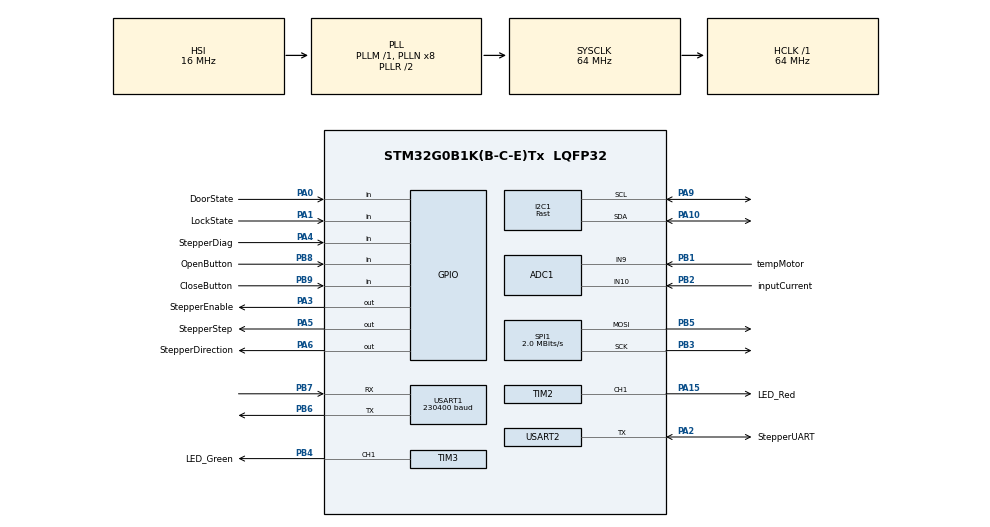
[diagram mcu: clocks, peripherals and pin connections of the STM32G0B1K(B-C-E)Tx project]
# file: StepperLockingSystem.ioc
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ADC1.DMAContinuousRequests=DISABLE
ADC1.DataAlign=ADC_DATAALIGN_RIGHT
ADC1.EOCSelection=ADC_EOC_SEQ_CONV
ADC1.NbrOfConversion=1
ADC1.NbrOfConversionFlag=0
ADC1.SamplingTimeCommon1=ADC_SAMPLETIME_160CYCLES_5
ADC1.SelectedChannel=ADC_CHANNEL_TEMPSENSOR|ADC_CHANNEL_VREFINT|ADC_CHANNEL_9|ADC_CHANNEL_10
ADC1.Sequencer=NOT_FULLY_CONFIGURABLE
ADC1.master=1
Dma.ADC1.0.Direction=DMA_PERIPH_TO_MEMORY
Dma.ADC1.0.EventEnable=DISABLE
Dma.ADC1.0.Instance=DMA1_Channel1
Dma.ADC1.0.MemDataAlignment=DMA_MDATAALIGN_HALFWORD
Dma.ADC1.0.MemInc=DMA_MINC_ENABLE
Dma.ADC1.0.Mode=DMA_NORMAL
Dma.ADC1.0.PeriphDataAlignment=DMA_PDATAALIGN_HALFWORD
Dma.ADC1.0.PeriphInc=DMA_PINC_DISABLE
Dma.ADC1.0.Polarity=HAL_DMAMUX_REQ_GEN_RISING
Dma.ADC1.0.Priority=DMA_PRIORITY_LOW
Dma.ADC1.0.RequestNumber=1
Dma.ADC1.0.SignalID=NONE
Dma.ADC1.0.SyncEnable=DISABLE
Dma.ADC1.0.SyncPolarity=HAL_DMAMUX_SYNC_NO_EVENT
Dma.ADC1.0.SyncRequestNumber=1
Dma.ADC1.0.SyncSignalID=NONE
Dma.Request0=ADC1
Dma.Request1=SPI1_TX
Dma.Request2=USART2_RX
Dma.Request3=USART2_TX
Dma.SPI1_TX.1.Direction=DMA_MEMORY_TO_PERIPH
Dma.SPI1_TX.1.EventEnable=DISABLE
Dma.SPI1_TX.1.Instance=DMA1_Channel2
Dma.SPI1_TX.1.MemDataAlignment=DMA_MDATAALIGN_BYTE
Dma.SPI1_TX.1.MemInc=DMA_MINC_ENABLE
Dma.SPI1_TX.1.Mode=DMA_NORMAL
Dma.SPI1_TX.1.PeriphDataAlignment=DMA_PDATAALIGN_BYTE
Dma.SPI1_TX.1.PeriphInc=DMA_PINC_DISABLE
Dma.SPI1_TX.1.Polarity=HAL_DMAMUX_REQ_GEN_RISING
Dma.SPI1_TX.1.Priority=DMA_PRIORITY_MEDIUM
Dma.SPI1_TX.1.RequestNumber=1
Dma.SPI1_TX.1.SignalID=NONE
Dma.SPI1_TX.1.SyncEnable=DISABLE
Dma.SPI1_TX.1.SyncPolarity=HAL_DMAMUX_SYNC_NO_EVENT
Dma.SPI1_TX.1.SyncRequestNumber=1
Dma.SPI1_TX.1.SyncSignalID=NONE
Dma.USART2_RX.2.Direction=DMA_PERIPH_TO_MEMORY
Dma.USART2_RX.2.EventEnable=DISABLE
Dma.USART2_RX.2.Instance=DMA1_Channel3
Dma.USART2_RX.2.MemDataAlignment=DMA_MDATAALIGN_BYTE
Dma.USART2_RX.2.MemInc=DMA_MINC_ENABLE
Dma.USART2_RX.2.Mode=DMA_NORMAL
Dma.USART2_RX.2.PeriphDataAlignment=DMA_PDATAALIGN_BYTE
Dma.USART2_RX.2.PeriphInc=DMA_PINC_DISABLE
Dma.USART2_RX.2.Polarity=HAL_DMAMUX_REQ_GEN_RISING
Dma.USART2_RX.2.Priority=DMA_PRIORITY_LOW
Dma.USART2_RX.2.RequestNumber=1
Dma.USART2_RX.2.SignalID=NONE
Dma.USART2_RX.2.SyncEnable=DISABLE
Dma.USART2_RX.2.SyncPolarity=HAL_DMAMUX_SYNC_NO_EVENT
Dma.USART2_RX.2.SyncRequestNumber=1
Dma.USART2_RX.2.SyncSignalID=NONE
Dma.USART2_TX.3.Direction=DMA_MEMORY_TO_PERIPH
Dma.USART2_TX.3.EventEnable=DISABLE
Dma.USART2_TX.3.Instance=DMA1_Channel4
Dma.USART2_TX.3.MemDataAlignment=DMA_MDATAALIGN_BYTE
Dma.USART2_TX.3.MemInc=DMA_MINC_ENABLE
Dma.USART2_TX.3.Mode=DMA_NORMAL
Dma.USART2_TX.3.PeriphDataAlignment=DMA_PDATAALIGN_BYTE
Dma.USART2_TX.3.PeriphInc=DMA_PINC_DISABLE
Dma.USART2_TX.3.Polarity=HAL_DMAMUX_REQ_GEN_RISING
Dma.USART2_TX.3.Priority=DMA_PRIORITY_LOW
Dma.USART2_TX.3.RequestNumber=1
Dma.USART2_TX.3.SignalID=NONE
Dma.USART2_TX.3.SyncEnable=DISABLE
Dma.USART2_TX.3.SyncPolarity=HAL_DMAMUX_SYNC_NO_EVENT
Dma.USART2_TX.3.SyncRequestNumber=1
Dma.USART2_TX.3.SyncSignalID=NONE
FREERTOS.Tasks01=defaultTask,24,512,StartDefaultTask,As weak,NULL,Dynamic,NULL,NULL
FREERTOS.configCHECK_FOR_STACK_OVERFLOW=2
FREERTOS.configMAX_TASK_NAME_LEN=24
FREERTOS.configRECORD_STACK_HIGH_ADDRESS=1
FREERTOS.configTIMER_TASK_STACK_DEPTH=256
FREERTOS.configTOTAL_HEAP_SIZE=30000
I2C1.I2C_Speed_Mode=I2C_Fast
I2C1.Timing=0x00602173
Mcu.Family=STM32G0
Mcu.Name=STM32G0B1K(B-C-E)Tx
Mcu.Package=LQFP32
NVIC.ADC1_COMP_IRQn=true\:3\:0\:true\:false\:true\:true\:true\:true\:true
NVIC.DMA1_Ch4_7_DMA2_Ch1_5_DMAMUX1_OVR_IRQn=true\:3\:0\:false\:false\:true\:true\:false\:true\:true
NVIC.DMA1_Channel1_IRQn=true\:3\:0\:false\:false\:true\:true\:false\:true\:true
NVIC.DMA1_Channel2_3_IRQn=true\:3\:0\:false\:false\:true\:true\:false\:true\:true
NVIC.I2C1_IRQn=true\:3\:0\:false\:false\:true\:true\:true\:true\:true
NVIC.SPI1_IRQn=true\:3\:0\:false\:false\:true\:true\:true\:true\:true
NVIC.TIM6_DAC_LPTIM1_IRQn=true\:3\:0\:false\:false\:true\:false\:false\:true\:true
NVIC.TimeBase=TIM6_DAC_LPTIM1_IRQn
NVIC.TimeBaseIP=TIM6
NVIC.USART2_LPUART2_IRQn=true\:3\:0\:false\:false\:true\:true\:true\:true\:true
PA0.GPIO_Label=DoorState
PA0.Signal=GPIO_Input
PA1.GPIO_Label=LockState
PA1.Signal=GPIO_Input
PA10.Mode=I2C
PA10.Signal=I2C1_SDA
PA13.Mode=Serial_Wire
PA13.Signal=SYS_SWDIO
PA14-BOOT0.Mode=Serial_Wire
PA14-BOOT0.Signal=SYS_SWCLK
PA15.GPIO_Label=LED_Red
PA15.Signal=S_TIM2_CH1_ETR
PA2.GPIO_Label=StepperUART
PA2.Mode=Half_duplex(single_wire_mode)
PA2.Signal=USART2_TX
PA3.GPIO_Label=StepperEnable
PA3.PinState=GPIO_PIN_SET
PA3.Signal=GPIO_Output
PA4.GPIO_Label=StepperDiag
PA4.Signal=GPIO_Input
PA5.GPIO_Label=StepperStep
PA5.Signal=GPIO_Output
PA6.GPIO_Label=StepperDirection
PA6.Signal=GPIO_Output
PA9.Mode=I2C
PA9.Signal=I2C1_SCL
PB1.GPIO_Label=tempMotor
PB1.Mode=IN9
PB1.Signal=ADC1_IN9
PB2.GPIO_Label=inputCurrent
PB2.Mode=IN10
PB2.Signal=ADC1_IN10
PB3.Mode=TX_Only_Simplex_Unidirect_Master
PB3.Signal=SPI1_SCK
PB4.GPIO_Label=LED_Green
PB4.Signal=S_TIM3_CH1
PB5.Mode=TX_Only_Simplex_Unidirect_Master
PB5.Signal=SPI1_MOSI
PB6.Mode=Asynchronous
PB6.Signal=USART1_TX
PB7.Mode=Asynchronous
PB7.Signal=USART1_RX
PB8.GPIO_Label=OpenButton
PB8.Signal=GPIO_Input
PB9.GPIO_Label=CloseButton
PB9.Signal=GPIO_Input
ProjectManager.HeapSize=0x200
ProjectManager.StackSize=0x400
ProjectManager.TargetToolchain=CMake
RCC.ADCFreq_Value=64000000
RCC.AHBFreq_Value=64000000
RCC.CortexFreq_Value=64000000
RCC.EXTERNAL_CLOCK_VALUE=48000
RCC.HCLKFreq_Value=64000000
RCC.HSE_VALUE=16000000
RCC.HSI48_VALUE=48000000
RCC.HSI_VALUE=16000000
RCC.LSE_VALUE=32768
RCC.SYSCLKFreq_VALUE=64000000
RCC.SYSCLKSource=RCC_SYSCLKSOURCE_PLLCLK
RCC.USBFreq_Value=48000000
RCC.VCOOutputFreq_Value=128000000
SH.S_TIM2_CH1_ETR.0=TIM2_CH1,PWM Generation1 CH1
SH.S_TIM3_CH1.0=TIM3_CH1,PWM Generation1 CH1
SPI1.BaudRatePrescaler=SPI_BAUDRATEPRESCALER_32
SPI1.CalculateBaudRate=2.0 MBits/s
SPI1.DataSize=SPI_DATASIZE_8BIT
SPI1.Direction=SPI_DIRECTION_2LINES
SPI1.Mode=SPI_MODE_MASTER
SPI1.VirtualType=VM_MASTER
TIM2.Channel-PWM\ Generation1\ CH1=TIM_CHANNEL_1
TIM2.ClockDivision=TIM_CLOCKDIVISION_DIV2
TIM2.Period=255
TIM2.TIM_MasterSlaveMode=TIM_MASTERSLAVEMODE_ENABLE
TIM3.Channel-PWM\ Generation1\ CH1=TIM_CHANNEL_1
TIM3.ClockDivision=TIM_CLOCKDIVISION_DIV2
TIM3.Period=255
USART1.BaudRate=230400
USART1.Mode=MODE_TX_RX
USART1.VirtualMode-Asynchronous=VM_ASYNC
USART2.VirtualMode-Half_duplex(single_wire_mode)=VM_ASYNC
VP_ADC1_TempSens_Input.Mode=IN-TempSens
VP_ADC1_Vref_Input.Mode=IN-Vrefint
VP_FREERTOS_VS_CMSIS_V2.Mode=CMSIS_V2
VP_SYS_VS_DBSignals.Mode=DisableDeadBatterySignals
VP_SYS_VS_tim6.Mode=TIM6
VP_TIM2_VS_ClockSourceINT.Mode=Internal
VP_TIM3_VS_ClockSourceINT.Mode=Internal
board=custom

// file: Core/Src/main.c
/* USER CODE BEGIN Header */
/**
  ******************************************************************************
  * @file           : main.c
  * @brief          : Main program body
  ******************************************************************************
  * @attention
  *
  * Copyright (c) 2025 STMicroelectronics.
  * All rights reserved.
  *
  * This software is licensed under terms that can be found in the LICENSE file
  * in the root directory of this software component.
  * If no LICENSE file comes with this software, it is provided AS-IS.
  *
  ******************************************************************************
  */
/* USER CODE END Header */
#include "main.h"
#include "cmsis_os.h"
#include "adc.h"
#include "dma.h"
#include "i2c.h"
#include "spi.h"
#include "tim.h"
#include "usart.h"
#include "gpio.h"

/* USER CODE BEGIN Includes */
#include "CFunctions.h"
#include "../../../src/customFaultHandler.h"
/* USER CODE END Includes */

void SystemClock_Config(void);
void MX_FREERTOS_Init(void);

int main(void)
{

  /* MCU Configuration--------------------------------------------------------*/

  /* Reset of all peripherals, Initializes the Flash interface and the Systick. */
  HAL_Init();

  /* Configure the system clock */
  SystemClock_Config();

  /* Initialize all configured peripherals */
  MX_GPIO_Init();
  MX_DMA_Init();
  MX_I2C1_Init();
  MX_SPI1_Init();
  MX_TIM2_Init();
  MX_TIM3_Init();
  MX_ADC1_Init();
  MX_USART2_UART_Init();
  MX_USART1_UART_Init();

  /* Init scheduler */
  osKernelInitialize();

  /* Call init function for freertos objects (in cmsis_os2.c) */
  MX_FREERTOS_Init();

  /* Start scheduler */
  osKernelStart();

  /* We should never get here as control is now taken by the scheduler */

  /* Infinite loop */
  while (1)
  {
    faultHandlerStepperFailsafe();
  }
}

void SystemClock_Config(void)
{
  RCC_OscInitTypeDef RCC_OscInitStruct = {0};
  RCC_ClkInitTypeDef RCC_ClkInitStruct = {0};

  /** Configure the main internal regulator output voltage
  */
  HAL_PWREx_ControlVoltageScaling(PWR_REGULATOR_VOLTAGE_SCALE1);

  /** Initializes the RCC Oscillators according to the specified parameters
  * in the RCC_OscInitTypeDef structure.
  */
  RCC_OscInitStruct.OscillatorType = RCC_OSCILLATORTYPE_HSI;
  RCC_OscInitStruct.HSIState = RCC_HSI_ON;
  RCC_OscInitStruct.HSIDiv = RCC_HSI_DIV1;
  RCC_OscInitStruct.HSICalibrationValue = RCC_HSICALIBRATION_DEFAULT;
  RCC_OscInitStruct.PLL.PLLState = RCC_PLL_ON;
  RCC_OscInitStruct.PLL.PLLSource = RCC_PLLSOURCE_HSI;
  RCC_OscInitStruct.PLL.PLLM = RCC_PLLM_DIV1;
  RCC_OscInitStruct.PLL.PLLN = 8;
  RCC_OscInitStruct.PLL.PLLP = RCC_PLLP_DIV2;
  RCC_OscInitStruct.PLL.PLLQ = RCC_PLLQ_DIV2;
  RCC_OscInitStruct.PLL.PLLR = RCC_PLLR_DIV2;
  if (HAL_RCC_OscConfig(&RCC_OscInitStruct) != HAL_OK)
  {
    Error_Handler();
  }

  /** Initializes the CPU, AHB and APB buses clocks
  */
  RCC_ClkInitStruct.ClockType = RCC_CLOCKTYPE_HCLK|RCC_CLOCKTYPE_SYSCLK
                              |RCC_CLOCKTYPE_PCLK1;
  RCC_ClkInitStruct.SYSCLKSource = RCC_SYSCLKSOURCE_PLLCLK;
  RCC_ClkInitStruct.AHBCLKDivider = RCC_SYSCLK_DIV1;
  RCC_ClkInitStruct.APB1CLKDivider = RCC_HCLK_DIV1;

  if (HAL_RCC_ClockConfig(&RCC_ClkInitStruct, FLASH_LATENCY_2) != HAL_OK)
  {
    Error_Handler();
  }
}

void HAL_TIM_PeriodElapsedCallback(TIM_HandleTypeDef *htim)
{
  if (htim->Instance == TIM6) {
    HAL_IncTick();
  }
  /* USER CODE BEGIN Callback 1 */
    else
    {
        // redirect timer Callbacks to TeensyStep
        hardwareTimerUpdateCallbackWrapper(htim);
    }
  /* USER CODE END Callback 1 */
}

void Error_Handler(void)
{
  /* USER CODE BEGIN Error_Handler_Debug */
  /* User can add his own implementation to report the HAL error return state */
  __disable_irq();

  // disable stepper motor to prevent overheating
  faultHandlerStepperFailsafe();
  /* USER CODE END Error_Handler_Debug */
}

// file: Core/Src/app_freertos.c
/* USER CODE BEGIN Header */
/**
  ******************************************************************************
  * File Name          : app_freertos.c
  * Description        : Code for freertos applications
  ******************************************************************************
  * @attention
  *
  * Copyright (c) 2025 STMicroelectronics.
  * All rights reserved.
  *
  * This software is licensed under terms that can be found in the LICENSE file
  * in the root directory of this software component.
  * If no LICENSE file comes with this software, it is provided AS-IS.
  *
  ******************************************************************************
  */
/* USER CODE END Header */

#include "FreeRTOS.h"
#include "task.h"
#include "main.h"
#include "cmsis_os.h"

/* Definitions for defaultTask */
osThreadId_t defaultTaskHandle;
const osThreadAttr_t defaultTask_attributes = {
  .name = "defaultTask",
  .priority = (osPriority_t) osPriorityNormal,
  .stack_size = 512 * 4
};

void StartDefaultTask(void *argument);

void MX_FREERTOS_Init(void); /* (MISRA C 2004 rule 8.1) */

/* Hook prototypes */
void vApplicationStackOverflowHook(xTaskHandle xTask, signed char *pcTaskName);

/* USER CODE BEGIN 4 */
void vApplicationStackOverflowHook(xTaskHandle xTask, signed char *pcTaskName)
{
   /* Run time stack overflow checking is performed if
   configCHECK_FOR_STACK_OVERFLOW is defined to 1 or 2. This hook function is
   called if a stack overflow is detected. */
}
/* USER CODE END 4 */

void MX_FREERTOS_Init(void) {

  /* Create the thread(s) */
  /* creation of defaultTask */
  defaultTaskHandle = osThreadNew(StartDefaultTask, NULL, &defaultTask_attributes);

}

__weak void StartDefaultTask(void *argument)
{
  for(;;)
  {
    osDelay(1);
  }
}
